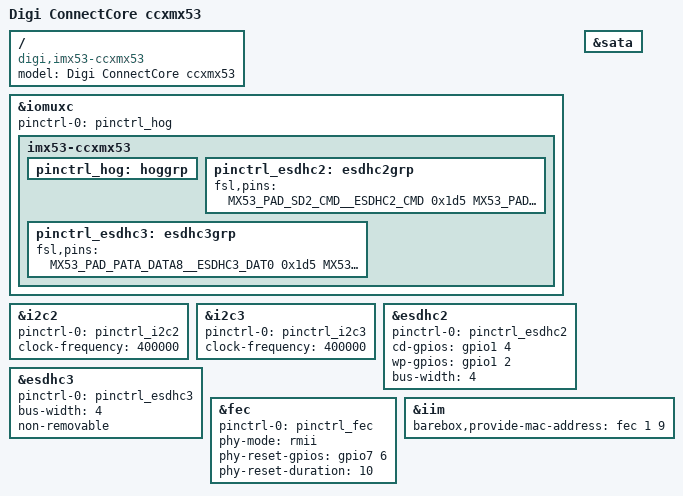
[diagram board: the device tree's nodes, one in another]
/*
 * Copyright 2011 Freescale Semiconductor, Inc.
 * Copyright 2011 Linaro Ltd.
 *
 * The code contained herein is licensed under the GNU General Public
 * License. You may obtain a copy of the GNU General Public License
 * Version 2 or later at the following locations:
 *
 * http://www.opensource.org/licenses/gpl-license.html
 * http://www.gnu.org/copyleft/gpl.html
 */

/dts-v1/;
#include "imx53-ccxmx53.dtsi"

/ {
	model = "Digi ConnectCore ccxmx53";
	compatible = "digi,imx53-ccxmx53", "fsl,imx53";
};

&iomuxc {
	pinctrl-names = "default";
	pinctrl-0 = <&pinctrl_hog>;

	imx53-ccxmx53 {
		pinctrl_hog: hoggrp {

		};

		pinctrl_esdhc2: esdhc2grp {
			fsl,pins = <
				MX53_PAD_SD2_CMD__ESDHC2_CMD		0x1d5
				MX53_PAD_SD2_CLK__ESDHC2_CLK		0x1d5
				MX53_PAD_SD2_DATA0__ESDHC2_DAT0		0x1d5
				MX53_PAD_SD2_DATA1__ESDHC2_DAT1		0x1d5
				MX53_PAD_SD2_DATA2__ESDHC2_DAT2		0x1d5
				MX53_PAD_SD2_DATA3__ESDHC2_DAT3		0x1d5
				/* SD2_CD */
				MX53_PAD_GPIO_4__GPIO1_4			0x1d5
				/* SD2_WP */
				MX53_PAD_GPIO_2__GPIO1_2			0x1d5
			>;
		};

		pinctrl_esdhc3: esdhc3grp {
			fsl,pins = <
				MX53_PAD_PATA_DATA8__ESDHC3_DAT0	0x1d5
				MX53_PAD_PATA_DATA9__ESDHC3_DAT1	0x1d5
				MX53_PAD_PATA_DATA10__ESDHC3_DAT2	0x1d5
				MX53_PAD_PATA_DATA11__ESDHC3_DAT3	0x1d5
				MX53_PAD_PATA_IORDY__ESDHC3_CLK		0x1d5
				MX53_PAD_PATA_RESET_B__ESDHC3_CMD	0x1d5
			>;
		};
	};
};

&i2c2 {
	pinctrl-names = "default";
	pinctrl-0 = <&pinctrl_i2c2>;
	clock-frequency = <400000>;
	status = "okay";
};

&i2c3 {
	pinctrl-names = "default";
	pinctrl-0 = <&pinctrl_i2c3>;
	clock-frequency = <400000>;
	status = "okay";
};

&esdhc2 {
	pinctrl-names = "default";
	pinctrl-0 = <&pinctrl_esdhc2>;
	cd-gpios = <&gpio1 4 GPIO_ACTIVE_HIGH>;
	wp-gpios = <&gpio1 2 GPIO_ACTIVE_HIGH>;
	bus-width = <4>;
	status = "okay";
};

&esdhc3 {
	pinctrl-names = "default";
	pinctrl-0 = <&pinctrl_esdhc3>;
	bus-width = <4>;
	non-removable;
	status = "okay";
};

&fec {
	pinctrl-names = "default";
	pinctrl-0 = <&pinctrl_fec>;
	phy-mode = "rmii";
	phy-reset-gpios = <&gpio7 6 0>;
	phy-reset-duration = <10>;
	status = "okay";
};

&sata {
	status = "okay";
};

&iim {
	barebox,provide-mac-address = <&fec 1 9>;
};
